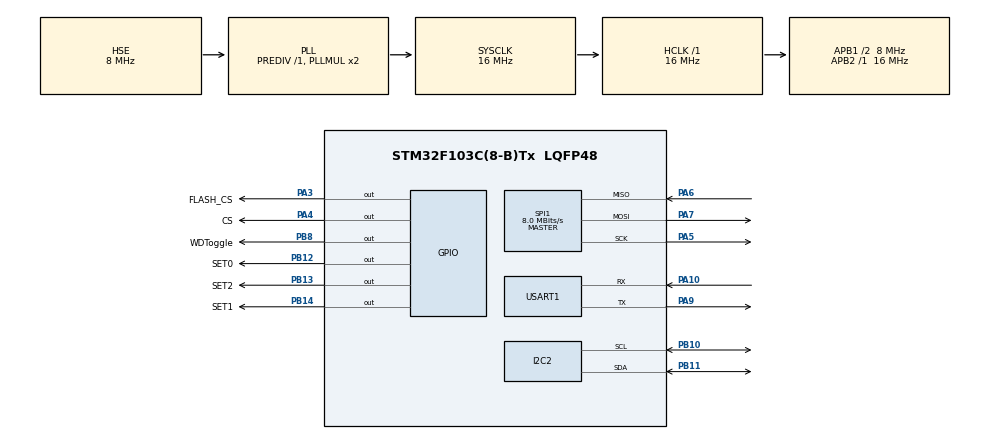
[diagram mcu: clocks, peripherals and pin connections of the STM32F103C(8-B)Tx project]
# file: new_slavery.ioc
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I2C2.OwnAddress=0x12
Mcu.Family=STM32F1
Mcu.Name=STM32F103C(8-B)Tx
Mcu.Package=LQFP48
NVIC.I2C2_ER_IRQn=true\:0\:0\:false\:false\:true\:true\:true\:true
NVIC.I2C2_EV_IRQn=true\:0\:0\:false\:false\:true\:true\:true\:true
NVIC.PriorityGroup=NVIC_PRIORITYGROUP_4
PA10.Mode=Asynchronous
PA10.Signal=USART1_RX
PA13.Mode=Serial_Wire
PA13.Signal=SYS_JTMS-SWDIO
PA14.Mode=Serial_Wire
PA14.Signal=SYS_JTCK-SWCLK
PA3.GPIO_Label=FLASH_CS
PA3.Signal=GPIO_Output
PA4.GPIO_Label=CS
PA4.Signal=GPIO_Output
PA5.Mode=Full_Duplex_Master
PA5.Signal=SPI1_SCK
PA6.Mode=Full_Duplex_Master
PA6.Signal=SPI1_MISO
PA7.Mode=Full_Duplex_Master
PA7.Signal=SPI1_MOSI
PA9.Mode=Asynchronous
PA9.Signal=USART1_TX
PB10.Mode=I2C
PB10.Signal=I2C2_SCL
PB11.Mode=I2C
PB11.Signal=I2C2_SDA
PB12.GPIO_Label=SET0
PB12.Signal=GPIO_Output
PB13.GPIO_Label=SET2
PB13.Signal=GPIO_Output
PB14.GPIO_Label=SET1
PB14.Signal=GPIO_Output
PB8.GPIO_Label=WDToggle
PB8.Signal=GPIO_Output
PD0-OSC_IN.Mode=HSE-External-Oscillator
PD0-OSC_IN.Signal=RCC_OSC_IN
PD1-OSC_OUT.Mode=HSE-External-Oscillator
PD1-OSC_OUT.Signal=RCC_OSC_OUT
ProjectManager.HeapSize=0x200
ProjectManager.StackSize=0x400
ProjectManager.TargetToolchain=Makefile
RCC.AHBFreq_Value=16000000
RCC.APB1CLKDivider=RCC_HCLK_DIV2
RCC.APB1Freq_Value=8000000
RCC.APB1TimFreq_Value=16000000
RCC.APB2Freq_Value=16000000
RCC.APB2TimFreq_Value=16000000
RCC.HCLKFreq_Value=16000000
RCC.PLLSourceVirtual=RCC_PLLSOURCE_HSE
RCC.SYSCLKFreq_VALUE=16000000
RCC.SYSCLKSource=RCC_SYSCLKSOURCE_PLLCLK
RCC.USBFreq_Value=16000000
SPI1.BaudRatePrescaler=SPI_BAUDRATEPRESCALER_2
SPI1.CalculateBaudRate=8.0 MBits/s
SPI1.Direction=SPI_DIRECTION_2LINES
SPI1.Mode=SPI_MODE_MASTER
SPI1.VirtualType=VM_MASTER
USART1.VirtualMode=VM_ASYNC
board=custom

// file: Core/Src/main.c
/* USER CODE BEGIN Header */
/**
  ******************************************************************************
  * @file           : main.c
  * @brief          : Main program body
  * @date           : 04-07-2025
  * @author         : Sarthak Chaudhary
  *****************************************************************************
  * @attention
  *
  * Copyright (c) 2025 STMicroelectronics.
  * All rights reserved.
  *
  * This software is licensed under terms that can be found in the LICENSE file
  * in the root directory of this software component.
  * If no LICENSE file comes with this software, it is provided AS-IS.
  *
  ******************************************************************************
  */
/* USER CODE END Header */
#include "main.h"
#include "i2c.h"
#include "spi.h"
#include "usart.h"
#include "gpio.h"

/* USER CODE BEGIN Includes */
#include <stdio.h>
#include <inttypes.h>
#include "camera.h"
#include "i2c_slave.h"
#include "watchdog.h"
int _write(int file, char *data, int len) {
    HAL_UART_Transmit(&huart1, (uint8_t*)data, len, HAL_MAX_DELAY);
    return len;
}
/* USER CODE END Includes */

void SystemClock_Config(void);

int main(void)
{

  /* MCU Configuration--------------------------------------------------------*/

  /* Reset of all peripherals, Initializes the Flash interface and the Systick. */
  HAL_Init();

  /* Configure the system clock */
  SystemClock_Config();

  /* Initialize all configured peripherals */
  MX_GPIO_Init();
  MX_I2C2_Init();
  MX_USART1_UART_Init();
  MX_SPI1_Init();
  /* USER CODE BEGIN 2 */
  uint32_t last_i2c_check_time = 0;
  extern uint32_t last_i2c_activity;  // Ensure declared in .c file

  printf("slave got started..........\r\n");
  if(HAL_I2C_EnableListen_IT(&hi2c2)!=HAL_OK)
  {
    Error_Handler();
  }
  watchdog_init();

  /* USER CODE END 2 */

  /* Infinite loop */
  /* USER CODE BEGIN WHILE */
   while (1)
  {

    if (capture_requested)
    {
      arducam_set_jpeg_mode();
      HAL_Delay(2000);
      process_image_capture();
      capture_requested = 0;
    }

    if (HAL_GetTick() - last_i2c_check_time > 1000)  // every 1s
    {
      last_i2c_check_time = HAL_GetTick();

      if ((HAL_GetTick() - last_i2c_activity > 3000) &&
          (__HAL_I2C_GET_FLAG(&hi2c2, I2C_FLAG_BUSY)))
      {
        printf("I2C timeout detected! Resetting I2C2...\r\n");

        __HAL_RCC_I2C2_FORCE_RESET();
        HAL_Delay(2);
        __HAL_RCC_I2C2_RELEASE_RESET();
        MX_I2C2_Init();
        HAL_I2C_EnableListen_IT(&hi2c2);

        capture_requested = 0;
        prestore_image_requested = 0;
        send_all_packets = 0;
        current_packet_index = 0;

        // Reset watchdog period after bus recovery
        watchdog_set_time_period(WD_DELAY_1_S);
      }
    }
  }

  //   /* USER CODE END WHILE */

  //   /* USER CODE BEGIN 3 */

  /* USER CODE END 3 */
}

void SystemClock_Config(void)
{
  RCC_OscInitTypeDef RCC_OscInitStruct = {0};
  RCC_ClkInitTypeDef RCC_ClkInitStruct = {0};

  /** Initializes the RCC Oscillators according to the specified parameters
  * in the RCC_OscInitTypeDef structure.
  */
  RCC_OscInitStruct.OscillatorType = RCC_OSCILLATORTYPE_HSE;
  RCC_OscInitStruct.HSEState = RCC_HSE_ON;
  RCC_OscInitStruct.HSEPredivValue = RCC_HSE_PREDIV_DIV1;
  RCC_OscInitStruct.HSIState = RCC_HSI_ON;
  RCC_OscInitStruct.PLL.PLLState = RCC_PLL_ON;
  RCC_OscInitStruct.PLL.PLLSource = RCC_PLLSOURCE_HSE;
  RCC_OscInitStruct.PLL.PLLMUL = RCC_PLL_MUL2;
  if (HAL_RCC_OscConfig(&RCC_OscInitStruct) != HAL_OK)
  {
    Error_Handler();
  }

  /** Initializes the CPU, AHB and APB buses clocks
  */
  RCC_ClkInitStruct.ClockType = RCC_CLOCKTYPE_HCLK|RCC_CLOCKTYPE_SYSCLK
                              |RCC_CLOCKTYPE_PCLK1|RCC_CLOCKTYPE_PCLK2;
  RCC_ClkInitStruct.SYSCLKSource = RCC_SYSCLKSOURCE_PLLCLK;
  RCC_ClkInitStruct.AHBCLKDivider = RCC_SYSCLK_DIV1;
  RCC_ClkInitStruct.APB1CLKDivider = RCC_HCLK_DIV2;
  RCC_ClkInitStruct.APB2CLKDivider = RCC_HCLK_DIV1;

  if (HAL_RCC_ClockConfig(&RCC_ClkInitStruct, FLASH_LATENCY_0) != HAL_OK)
  {
    Error_Handler();
  }
}

void Error_Handler(void)
{
  __disable_irq();
  while (1)
  {
  }
}
